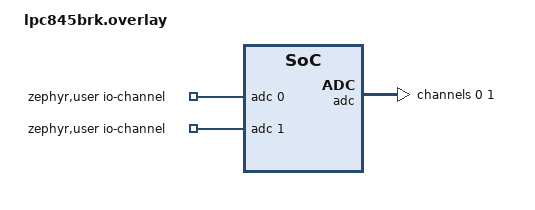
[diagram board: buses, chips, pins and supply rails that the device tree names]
/*
 * Copyright (c) 2026 Aerlync Labs Inc.
 *
 * SPDX-License-Identifier: Apache-2.0
 */

#include <zephyr/dt-bindings/adc/adc.h>

/ {
	aliases {
		adc = &adc;
	};

	zephyr,user {
		io-channels = <&adc 0>, <&adc 1>;
	};
};

&adc {
	#address-cells = <1>;
	#size-cells = <0>;
	pinctrl-0 = <&adc0_default>;
	pinctrl-names = "default";
	status = "okay";

	channel@0 {
		reg = <0>;
		zephyr,gain = "ADC_GAIN_1";
		zephyr,reference = "ADC_REF_INTERNAL";
		zephyr,acquisition-time = <ADC_ACQ_TIME_DEFAULT>;
		zephyr,resolution = <12>;
	};

	channel@1 {
		reg = <1>;
		zephyr,gain = "ADC_GAIN_1";
		zephyr,reference = "ADC_REF_INTERNAL";
		zephyr,acquisition-time = <ADC_ACQ_TIME_DEFAULT>;
		zephyr,resolution = <12>;
	};
};

&swm {
	adc0_default: adc0_default {
		group0 {
			pinmux = <LPC84X_PINMUX_F(LPC84X_SWM_ADC_CHN0, P0_7)>,
				 <LPC84X_PINMUX_F(LPC84X_SWM_ADC_CHN1, P0_6)>;
		};
	};
};
